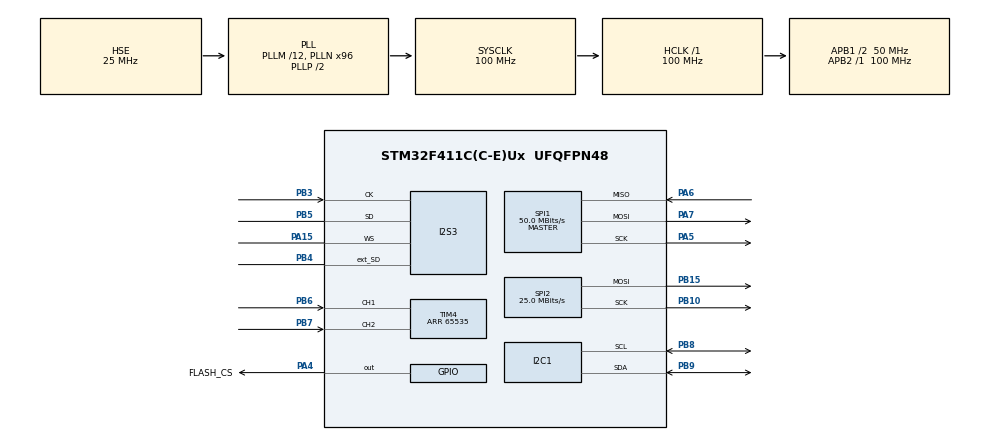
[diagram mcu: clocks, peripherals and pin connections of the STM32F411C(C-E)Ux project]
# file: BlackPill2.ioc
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Mcu.Family=STM32F4
Dma.SPI3_RX.3.Direction=DMA_PERIPH_TO_MEMORY
PA6.Mode=Full_Duplex_Master
RCC.CortexFreq_Value=100000000
SPI1.VirtualType=VM_MASTER
SPI2.VirtualType=VM_MASTER
PB10.Mode=TX_Only_Simplex_Unidirect_Master
TIM4.EncoderMode=TIM_ENCODERMODE_TI12
VP_RTC_VS_RTC_Activate.Mode=RTC_Enabled
Dma.I2S3_EXT_TX.2.PeriphInc=DMA_PINC_DISABLE
Dma.MEMTOMEM.1.FIFOMode=DMA_FIFOMODE_ENABLE
Dma.MEMTOMEM.1.PeriphInc=DMA_PINC_ENABLE
PB15.Signal=SPI2_MOSI
Dma.MEMTOMEM.1.Priority=DMA_PRIORITY_HIGH
RCC.SYSCLKSource=RCC_SYSCLKSOURCE_PLLCLK
ProjectManager.StackSize=0x800
PH0\ -\ OSC_IN.Signal=RCC_OSC_IN
Dma.SPI3_RX.3.MemDataAlignment=DMA_MDATAALIGN_HALFWORD
SPI1.Direction=SPI_DIRECTION_2LINES
RCC.HCLKFreq_Value=100000000
Dma.I2S3_EXT_TX.2.FIFOMode=DMA_FIFOMODE_DISABLE
I2S3.Mode=I2S_MODE_SLAVE_RX
RCC.APB2TimFreq_Value=100000000
PB6.Signal=S_TIM4_CH1
SPI1.CalculateBaudRate=50.0 MBits/s
NVIC.DMA2_Stream0_IRQn=true\:0\:0\:false\:false\:true\:false\:true\:true
RCC.AHBFreq_Value=100000000
RCC.HSE_VALUE=25000000
Dma.SPI3_RX.3.Mode=DMA_CIRCULAR
PB3.Mode=Full_Duplex_Slave
Dma.SPI3_RX.3.Priority=DMA_PRIORITY_VERY_HIGH
PA15.Mode=Full_Duplex_Slave
PA4.GPIO_Speed=GPIO_SPEED_FREQ_HIGH
Dma.MEMTOMEM.1.MemBurst=DMA_MBURST_SINGLE
I2S3.ErrorAudioFreq=-0.35 %
PB4.Mode=Full_Duplex_Slave
PC14-OSC32_IN.Mode=LSE-External-Oscillator
FREERTOS.INCLUDE_xQueueGetMutexHolder=1
PA14.Mode=Serial_Wire
VP_SYS_VS_tim1.Mode=TIM1
Dma.MEMTOMEM.0.Instance=DMA2_Stream0
PB5.Mode=Full_Duplex_Slave
Dma.I2S3_EXT_TX.2.Mode=DMA_CIRCULAR
SPI2.CalculateBaudRate=25.0 MBits/s
SH.S_TIM4_CH2.0=TIM4_CH2,Encoder_Interface
PB7.Signal=S_TIM4_CH2
TIM4.Period=65535
VP_FREERTOS_VS_CMSIS_V1.Mode=CMSIS_V1
Dma.I2S3_EXT_TX.2.Instance=DMA1_Stream5
Dma.I2S3_EXT_TX.2.Direction=DMA_MEMORY_TO_PERIPH
Dma.MEMTOMEM.1.MemInc=DMA_MINC_ENABLE
PB9.Signal=I2C1_SDA
Mcu.Package=UFQFPN48
PA6.Signal=SPI1_MISO
Dma.MEMTOMEM.1.Instance=DMA2_Stream1
NVIC.TimeBase=TIM1_UP_TIM10_IRQn
SPI2.Mode=SPI_MODE_MASTER
Dma.MEMTOMEM.1.PeriphBurst=DMA_PBURST_SINGLE
Dma.MEMTOMEM.0.PeriphInc=DMA_PINC_ENABLE
NVIC.TimeBaseIP=TIM1
PA15.Signal=I2S3_WS
Dma.MEMTOMEM.0.FIFOThreshold=DMA_FIFO_THRESHOLD_FULL
Dma.MEMTOMEM.1.FIFOThreshold=DMA_FIFO_THRESHOLD_FULL
SH.S_TIM4_CH1.0=TIM4_CH1,Encoder_Interface
Dma.Request2=I2S3_EXT_TX
Dma.Request1=MEMTOMEM
RCC.APB1TimFreq_Value=100000000
Dma.Request3=SPI3_RX
Dma.I2S3_EXT_TX.2.PeriphDataAlignment=DMA_PDATAALIGN_HALFWORD
NVIC.DMA1_Stream0_IRQn=true\:5\:0\:false\:false\:true\:true\:false\:true
SPI2.Direction=SPI_DIRECTION_2LINES
Dma.Request0=MEMTOMEM
PA4.GPIO_Label=FLASH_CS
PB4.Signal=I2S3_ext_SD
PA5.Mode=Full_Duplex_Master
RCC.PLLSourceVirtual=RCC_PLLSOURCE_HSE
PC15-OSC32_OUT.Mode=LSE-External-Oscillator
I2S3.FullDuplexMode=I2S_FULLDUPLEXMODE_ENABLE
Dma.MEMTOMEM.0.MemDataAlignment=DMA_MDATAALIGN_HALFWORD
FREERTOS.Tasks01=defaultTask,0,1280,StartDefaultTask,Default,NULL,Dynamic,NULL,NULL;myTask02,0,1280,StartTask02,Default,NULL,Dynamic,NULL,NULL
Dma.I2S3_EXT_TX.2.MemDataAlignment=DMA_MDATAALIGN_HALFWORD
PA7.Mode=Full_Duplex_Master
Dma.MEMTOMEM.0.Priority=DMA_PRIORITY_HIGH
PH1\ -\ OSC_OUT.Mode=HSE-External-Oscillator
ARM.CMSIS.5.6.0.CMSISJjDSP=Library
RCC.APB1CLKDivider=RCC_HCLK_DIV2
PC14-OSC32_IN.Signal=RCC_OSC32_IN
I2S3.DataFormat=I2S_DATAFORMAT_16B
PA13.Signal=SYS_JTMS-SWDIO
PH0\ -\ OSC_IN.Mode=HSE-External-Oscillator
Dma.SPI3_RX.3.MemInc=DMA_MINC_ENABLE
ProjectManager.TargetToolchain=STM32CubeIDE
NVIC.DMA1_Stream5_IRQn=true\:5\:0\:false\:false\:true\:true\:false\:true
VP_ARM.CMSIS_VS_CMSISJjDSP_1.7.0.Mode=CMSISJjDSP
PB9.Mode=I2C
I2S3.VirtualMode=I2S_MODE_SLAVE
Dma.SPI3_RX.3.PeriphInc=DMA_PINC_DISABLE
Dma.MEMTOMEM.0.FIFOMode=DMA_FIFOMODE_ENABLE
PC15-OSC32_OUT.Signal=RCC_OSC32_OUT
PB10.Signal=SPI2_SCK
Dma.MEMTOMEM.0.MemBurst=DMA_MBURST_SINGLE
ARM.CMSIS.5.6.0.CMSISJjCORE=true
PA5.Signal=SPI1_SCK
Dma.MEMTOMEM.1.Mode=DMA_NORMAL
I2S3.AudioFreq=I2S_AUDIOFREQ_96K
PH1\ -\ OSC_OUT.Signal=RCC_OSC_OUT
VP_ARM.CMSIS_VS_CMSISJjCORE_5.3.0.Mode=CMSISJjCORE
board=custom
RCC.VCOOutputFreq_Value=200000000
PB15.Mode=TX_Only_Simplex_Unidirect_Master
Dma.MEMTOMEM.1.MemDataAlignment=DMA_MDATAALIGN_HALFWORD
RCC.APB2Freq_Value=100000000
Dma.MEMTOMEM.1.PeriphDataAlignment=DMA_PDATAALIGN_HALFWORD
SPI1.Mode=SPI_MODE_MASTER
Dma.SPI3_RX.3.FIFOMode=DMA_FIFOMODE_DISABLE
Dma.MEMTOMEM.1.Direction=DMA_MEMORY_TO_MEMORY
PA13.Mode=Serial_Wire
Mcu.Name=STM32F411C(C-E)Ux
FREERTOS.INCLUDE_xSemaphoreGetMutexHolder=1
Dma.MEMTOMEM.0.PeriphDataAlignment=DMA_PDATAALIGN_HALFWORD
RCC.48MHZClocksFreq_Value=40000000
PB3.Signal=I2S3_CK
PA4.Signal=GPIO_Output
RCC.SYSCLKFreq_VALUE=100000000
PB5.Signal=I2S3_SD
FREERTOS.configUSE_COUNTING_SEMAPHORES=1
Dma.MEMTOMEM.0.Mode=DMA_NORMAL
Dma.MEMTOMEM.0.PeriphBurst=DMA_PBURST_SINGLE
Dma.MEMTOMEM.0.MemInc=DMA_MINC_ENABLE
Dma.I2S3_EXT_TX.2.Priority=DMA_PRIORITY_VERY_HIGH
PA14.Signal=SYS_JTCK-SWCLK
ProjectManager.HeapSize=0x200
Dma.SPI3_RX.3.PeriphDataAlignment=DMA_PDATAALIGN_HALFWORD
FREERTOS.configUSE_RECURSIVE_MUTEXES=1
NVIC.TIM1_UP_TIM10_IRQn=true\:0\:0\:false\:false\:true\:false\:false\:true
RCC.HSI_VALUE=16000000
RCC.PLLQ=5
NVIC.PriorityGroup=NVIC_PRIORITYGROUP_4
I2S3.RealAudioFreq=95.663 KHz
RCC.PLLM=12
PB8.Mode=I2C
RCC.PLLN=96
PB8.Signal=I2C1_SCL
Dma.MEMTOMEM.0.Direction=DMA_MEMORY_TO_MEMORY
Dma.SPI3_RX.3.Instance=DMA1_Stream0
I2S3.Instance=SPI$Index
RCC.APB1Freq_Value=50000000
Dma.I2S3_EXT_TX.2.MemInc=DMA_MINC_ENABLE
PA7.Signal=SPI1_MOSI

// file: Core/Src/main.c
/* USER CODE BEGIN Header */
/**
 ******************************************************************************
 * @file           : main.c
 * @brief          : Main program body
 ******************************************************************************
 * @attention
 *
 * <h2><center>&copy; Copyright (c) 2020 STMicroelectronics.
 * All rights reserved.</center></h2>
 *
 * This software component is licensed by ST under BSD 3-Clause license,
 * the "License"; You may not use this file except in compliance with the
 * License. You may obtain a copy of the License at:
 *                        opensource.org/licenses/BSD-3-Clause
 *
 ******************************************************************************
 */
/* USER CODE END Header */

#include "main.h"
#include "cmsis_os.h"

I2C_HandleTypeDef hi2c1;

I2S_HandleTypeDef hi2s3;
DMA_HandleTypeDef hdma_i2s3_ext_rx;
DMA_HandleTypeDef hdma_spi3_tx;

RTC_HandleTypeDef hrtc;

SPI_HandleTypeDef hspi1;
SPI_HandleTypeDef hspi2;

TIM_HandleTypeDef htim4;

DMA_HandleTypeDef hdma_memtomem_dma2_stream0;
DMA_HandleTypeDef hdma_memtomem_dma2_stream1;
osThreadId defaultTaskHandle;
osThreadId myTask02Handle;

void SystemClock_Config(void);
static void MX_GPIO_Init(void);
static void MX_DMA_Init(void);
static void MX_RTC_Init(void);
static void MX_SPI1_Init(void);
static void MX_TIM4_Init(void);
static void MX_I2C1_Init(void);
static void MX_I2S3_Init(void);
static void MX_SPI2_Init(void);
void StartDefaultTask(void const * argument);
void StartTask02(void const * argument);

/* USER CODE BEGIN PFP */
void DMA2_Stream0_TransferComplete(DMA_HandleTypeDef *DmaHandle);
void init(void);
void render(void);
void update(void);
/* USER CODE END PFP */

int main(void)
{

  /* MCU Configuration--------------------------------------------------------*/

  /* Reset of all peripherals, Initializes the Flash interface and the Systick. */
  HAL_Init();

  /* Configure the system clock */
  SystemClock_Config();

  /* Initialize all configured peripherals */
  MX_GPIO_Init();
  MX_DMA_Init();
  MX_RTC_Init();
  MX_SPI1_Init();
  MX_TIM4_Init();
  MX_I2C1_Init();
  MX_I2S3_Init();
  MX_SPI2_Init();
  /* USER CODE BEGIN 2 */

	HAL_DMA_RegisterCallback(&hdma_memtomem_dma2_stream0,
			HAL_DMA_XFER_CPLT_CB_ID, DMA2_Stream0_TransferComplete);

  /* USER CODE END 2 */

  /* Create the thread(s) */
  /* definition and creation of defaultTask */
  osThreadDef(defaultTask, StartDefaultTask, osPriorityNormal, 0, 1280);
  defaultTaskHandle = osThreadCreate(osThread(defaultTask), NULL);

  /* definition and creation of myTask02 */
  osThreadDef(myTask02, StartTask02, osPriorityNormal, 0, 1280);
  myTask02Handle = osThreadCreate(osThread(myTask02), NULL);

  /* Start scheduler */
  osKernelStart();

  /* We should never get here as control is now taken by the scheduler */
  /* Infinite loop */
	while (1) {

	}
}

void SystemClock_Config(void)
{
  RCC_OscInitTypeDef RCC_OscInitStruct = {0};
  RCC_ClkInitTypeDef RCC_ClkInitStruct = {0};
  RCC_PeriphCLKInitTypeDef PeriphClkInitStruct = {0};

  /** Configure the main internal regulator output voltage
  */
  __HAL_RCC_PWR_CLK_ENABLE();
  __HAL_PWR_VOLTAGESCALING_CONFIG(PWR_REGULATOR_VOLTAGE_SCALE1);
  /** Initializes the CPU, AHB and APB busses clocks
  */
  RCC_OscInitStruct.OscillatorType = RCC_OSCILLATORTYPE_LSI|RCC_OSCILLATORTYPE_HSE;
  RCC_OscInitStruct.HSEState = RCC_HSE_ON;
  RCC_OscInitStruct.LSIState = RCC_LSI_ON;
  RCC_OscInitStruct.PLL.PLLState = RCC_PLL_ON;
  RCC_OscInitStruct.PLL.PLLSource = RCC_PLLSOURCE_HSE;
  RCC_OscInitStruct.PLL.PLLM = 12;
  RCC_OscInitStruct.PLL.PLLN = 96;
  RCC_OscInitStruct.PLL.PLLP = RCC_PLLP_DIV2;
  RCC_OscInitStruct.PLL.PLLQ = 5;
  if (HAL_RCC_OscConfig(&RCC_OscInitStruct) != HAL_OK)
  {
    Error_Handler();
  }
  /** Initializes the CPU, AHB and APB busses clocks
  */
  RCC_ClkInitStruct.ClockType = RCC_CLOCKTYPE_HCLK|RCC_CLOCKTYPE_SYSCLK
                              |RCC_CLOCKTYPE_PCLK1|RCC_CLOCKTYPE_PCLK2;
  RCC_ClkInitStruct.SYSCLKSource = RCC_SYSCLKSOURCE_PLLCLK;
  RCC_ClkInitStruct.AHBCLKDivider = RCC_SYSCLK_DIV1;
  RCC_ClkInitStruct.APB1CLKDivider = RCC_HCLK_DIV2;
  RCC_ClkInitStruct.APB2CLKDivider = RCC_HCLK_DIV1;

  if (HAL_RCC_ClockConfig(&RCC_ClkInitStruct, FLASH_LATENCY_3) != HAL_OK)
  {
    Error_Handler();
  }
  PeriphClkInitStruct.PeriphClockSelection = RCC_PERIPHCLK_I2S|RCC_PERIPHCLK_RTC;
  PeriphClkInitStruct.PLLI2S.PLLI2SN = 192;
  PeriphClkInitStruct.PLLI2S.PLLI2SM = 16;
  PeriphClkInitStruct.PLLI2S.PLLI2SR = 2;
  PeriphClkInitStruct.RTCClockSelection = RCC_RTCCLKSOURCE_LSI;
  if (HAL_RCCEx_PeriphCLKConfig(&PeriphClkInitStruct) != HAL_OK)
  {
    Error_Handler();
  }
}

static void MX_I2C1_Init(void)
{

  hi2c1.Instance = I2C1;
  hi2c1.Init.ClockSpeed = 100000;
  hi2c1.Init.DutyCycle = I2C_DUTYCYCLE_2;
  hi2c1.Init.OwnAddress1 = 0;
  hi2c1.Init.AddressingMode = I2C_ADDRESSINGMODE_7BIT;
  hi2c1.Init.DualAddressMode = I2C_DUALADDRESS_DISABLE;
  hi2c1.Init.OwnAddress2 = 0;
  hi2c1.Init.GeneralCallMode = I2C_GENERALCALL_DISABLE;
  hi2c1.Init.NoStretchMode = I2C_NOSTRETCH_DISABLE;
  if (HAL_I2C_Init(&hi2c1) != HAL_OK)
  {
    Error_Handler();
  }

}

static void MX_I2S3_Init(void)
{

  hi2s3.Instance = SPI3;
  hi2s3.Init.Mode = I2S_MODE_SLAVE_TX;
  hi2s3.Init.Standard = I2S_STANDARD_PHILIPS;
  hi2s3.Init.DataFormat = I2S_DATAFORMAT_16B;
  hi2s3.Init.MCLKOutput = I2S_MCLKOUTPUT_DISABLE;
  hi2s3.Init.AudioFreq = I2S_AUDIOFREQ_96K;
  hi2s3.Init.CPOL = I2S_CPOL_LOW;
  hi2s3.Init.ClockSource = I2S_CLOCK_PLL;
  hi2s3.Init.FullDuplexMode = I2S_FULLDUPLEXMODE_ENABLE;
  if (HAL_I2S_Init(&hi2s3) != HAL_OK)
  {
    Error_Handler();
  }

}

static void MX_RTC_Init(void)
{

  /** Initialize RTC Only
  */
  hrtc.Instance = RTC;
  hrtc.Init.HourFormat = RTC_HOURFORMAT_24;
  hrtc.Init.AsynchPrediv = 127;
  hrtc.Init.SynchPrediv = 255;
  hrtc.Init.OutPut = RTC_OUTPUT_DISABLE;
  hrtc.Init.OutPutPolarity = RTC_OUTPUT_POLARITY_HIGH;
  hrtc.Init.OutPutType = RTC_OUTPUT_TYPE_OPENDRAIN;
  if (HAL_RTC_Init(&hrtc) != HAL_OK)
  {
    Error_Handler();
  }

}

static void MX_SPI1_Init(void)
{

  /* SPI1 parameter configuration*/
  hspi1.Instance = SPI1;
  hspi1.Init.Mode = SPI_MODE_MASTER;
  hspi1.Init.Direction = SPI_DIRECTION_2LINES;
  hspi1.Init.DataSize = SPI_DATASIZE_8BIT;
  hspi1.Init.CLKPolarity = SPI_POLARITY_LOW;
  hspi1.Init.CLKPhase = SPI_PHASE_1EDGE;
  hspi1.Init.NSS = SPI_NSS_SOFT;
  hspi1.Init.BaudRatePrescaler = SPI_BAUDRATEPRESCALER_2;
  hspi1.Init.FirstBit = SPI_FIRSTBIT_MSB;
  hspi1.Init.TIMode = SPI_TIMODE_DISABLE;
  hspi1.Init.CRCCalculation = SPI_CRCCALCULATION_DISABLE;
  hspi1.Init.CRCPolynomial = 10;
  if (HAL_SPI_Init(&hspi1) != HAL_OK)
  {
    Error_Handler();
  }

}

static void MX_SPI2_Init(void)
{

  /* SPI2 parameter configuration*/
  hspi2.Instance = SPI2;
  hspi2.Init.Mode = SPI_MODE_MASTER;
  hspi2.Init.Direction = SPI_DIRECTION_2LINES;
  hspi2.Init.DataSize = SPI_DATASIZE_8BIT;
  hspi2.Init.CLKPolarity = SPI_POLARITY_LOW;
  hspi2.Init.CLKPhase = SPI_PHASE_1EDGE;
  hspi2.Init.NSS = SPI_NSS_SOFT;
  hspi2.Init.BaudRatePrescaler = SPI_BAUDRATEPRESCALER_2;
  hspi2.Init.FirstBit = SPI_FIRSTBIT_MSB;
  hspi2.Init.TIMode = SPI_TIMODE_DISABLE;
  hspi2.Init.CRCCalculation = SPI_CRCCALCULATION_DISABLE;
  hspi2.Init.CRCPolynomial = 10;
  if (HAL_SPI_Init(&hspi2) != HAL_OK)
  {
    Error_Handler();
  }

}

static void MX_TIM4_Init(void)
{

  TIM_Encoder_InitTypeDef sConfig = {0};
  TIM_MasterConfigTypeDef sMasterConfig = {0};

  htim4.Instance = TIM4;
  htim4.Init.Prescaler = 0;
  htim4.Init.CounterMode = TIM_COUNTERMODE_UP;
  htim4.Init.Period = 65535;
  htim4.Init.ClockDivision = TIM_CLOCKDIVISION_DIV1;
  htim4.Init.AutoReloadPreload = TIM_AUTORELOAD_PRELOAD_DISABLE;
  sConfig.EncoderMode = TIM_ENCODERMODE_TI12;
  sConfig.IC1Polarity = TIM_ICPOLARITY_RISING;
  sConfig.IC1Selection = TIM_ICSELECTION_DIRECTTI;
  sConfig.IC1Prescaler = TIM_ICPSC_DIV1;
  sConfig.IC1Filter = 0;
  sConfig.IC2Polarity = TIM_ICPOLARITY_RISING;
  sConfig.IC2Selection = TIM_ICSELECTION_DIRECTTI;
  sConfig.IC2Prescaler = TIM_ICPSC_DIV1;
  sConfig.IC2Filter = 0;
  if (HAL_TIM_Encoder_Init(&htim4, &sConfig) != HAL_OK)
  {
    Error_Handler();
  }
  sMasterConfig.MasterOutputTrigger = TIM_TRGO_RESET;
  sMasterConfig.MasterSlaveMode = TIM_MASTERSLAVEMODE_DISABLE;
  if (HAL_TIMEx_MasterConfigSynchronization(&htim4, &sMasterConfig) != HAL_OK)
  {
    Error_Handler();
  }

}

static void MX_DMA_Init(void)
{

  /* DMA controller clock enable */
  __HAL_RCC_DMA2_CLK_ENABLE();
  __HAL_RCC_DMA1_CLK_ENABLE();

  /* Configure DMA request hdma_memtomem_dma2_stream0 on DMA2_Stream0 */
  hdma_memtomem_dma2_stream0.Instance = DMA2_Stream0;
  hdma_memtomem_dma2_stream0.Init.Channel = DMA_CHANNEL_0;
  hdma_memtomem_dma2_stream0.Init.Direction = DMA_MEMORY_TO_MEMORY;
  hdma_memtomem_dma2_stream0.Init.PeriphInc = DMA_PINC_ENABLE;
  hdma_memtomem_dma2_stream0.Init.MemInc = DMA_MINC_ENABLE;
  hdma_memtomem_dma2_stream0.Init.PeriphDataAlignment = DMA_PDATAALIGN_HALFWORD;
  hdma_memtomem_dma2_stream0.Init.MemDataAlignment = DMA_MDATAALIGN_HALFWORD;
  hdma_memtomem_dma2_stream0.Init.Mode = DMA_NORMAL;
  hdma_memtomem_dma2_stream0.Init.Priority = DMA_PRIORITY_HIGH;
  hdma_memtomem_dma2_stream0.Init.FIFOMode = DMA_FIFOMODE_ENABLE;
  hdma_memtomem_dma2_stream0.Init.FIFOThreshold = DMA_FIFO_THRESHOLD_FULL;
  hdma_memtomem_dma2_stream0.Init.MemBurst = DMA_MBURST_SINGLE;
  hdma_memtomem_dma2_stream0.Init.PeriphBurst = DMA_PBURST_SINGLE;
  if (HAL_DMA_Init(&hdma_memtomem_dma2_stream0) != HAL_OK)
  {
    Error_Handler( );
  }

  /* Configure DMA request hdma_memtomem_dma2_stream1 on DMA2_Stream1 */
  hdma_memtomem_dma2_stream1.Instance = DMA2_Stream1;
  hdma_memtomem_dma2_stream1.Init.Channel = DMA_CHANNEL_0;
  hdma_memtomem_dma2_stream1.Init.Direction = DMA_MEMORY_TO_MEMORY;
  hdma_memtomem_dma2_stream1.Init.PeriphInc = DMA_PINC_ENABLE;
  hdma_memtomem_dma2_stream1.Init.MemInc = DMA_MINC_ENABLE;
  hdma_memtomem_dma2_stream1.Init.PeriphDataAlignment = DMA_PDATAALIGN_HALFWORD;
  hdma_memtomem_dma2_stream1.Init.MemDataAlignment = DMA_MDATAALIGN_HALFWORD;
  hdma_memtomem_dma2_stream1.Init.Mode = DMA_NORMAL;
  hdma_memtomem_dma2_stream1.Init.Priority = DMA_PRIORITY_HIGH;
  hdma_memtomem_dma2_stream1.Init.FIFOMode = DMA_FIFOMODE_ENABLE;
  hdma_memtomem_dma2_stream1.Init.FIFOThreshold = DMA_FIFO_THRESHOLD_FULL;
  hdma_memtomem_dma2_stream1.Init.MemBurst = DMA_MBURST_SINGLE;
  hdma_memtomem_dma2_stream1.Init.PeriphBurst = DMA_PBURST_SINGLE;
  if (HAL_DMA_Init(&hdma_memtomem_dma2_stream1) != HAL_OK)
  {
    Error_Handler( );
  }

  /* DMA interrupt init */
  /* DMA1_Stream0_IRQn interrupt configuration */
  HAL_NVIC_SetPriority(DMA1_Stream0_IRQn, 5, 0);
  HAL_NVIC_EnableIRQ(DMA1_Stream0_IRQn);
  /* DMA1_Stream5_IRQn interrupt configuration */
  HAL_NVIC_SetPriority(DMA1_Stream5_IRQn, 5, 0);
  HAL_NVIC_EnableIRQ(DMA1_Stream5_IRQn);
  /* DMA2_Stream0_IRQn interrupt configuration */
  HAL_NVIC_SetPriority(DMA2_Stream0_IRQn, 0, 0);
  HAL_NVIC_EnableIRQ(DMA2_Stream0_IRQn);

}

static void MX_GPIO_Init(void)
{
  GPIO_InitTypeDef GPIO_InitStruct = {0};

  /* GPIO Ports Clock Enable */
  __HAL_RCC_GPIOC_CLK_ENABLE();
  __HAL_RCC_GPIOH_CLK_ENABLE();
  __HAL_RCC_GPIOA_CLK_ENABLE();
  __HAL_RCC_GPIOB_CLK_ENABLE();

  /*Configure GPIO pin Output Level */
  HAL_GPIO_WritePin(FLASH_CS_GPIO_Port, FLASH_CS_Pin, GPIO_PIN_RESET);

  /*Configure GPIO pin : FLASH_CS_Pin */
  GPIO_InitStruct.Pin = FLASH_CS_Pin;
  GPIO_InitStruct.Mode = GPIO_MODE_OUTPUT_PP;
  GPIO_InitStruct.Pull = GPIO_NOPULL;
  GPIO_InitStruct.Speed = GPIO_SPEED_FREQ_HIGH;
  HAL_GPIO_Init(FLASH_CS_GPIO_Port, &GPIO_InitStruct);

}

void StartDefaultTask(void const * argument)
{
  /* USER CODE BEGIN 5 */
	init();
	/* Infinite loop */
	for (;;) {
		render();
		osDelay(1);
	}
  /* USER CODE END 5 */
}

void StartTask02(void const * argument)
{
  /* USER CODE BEGIN StartTask02 */
  /* Infinite loop */
  for(;;)
  {
	  update();
    osDelay(1);
  }
  /* USER CODE END StartTask02 */
}

 /**
  * @brief  Period elapsed callback in non blocking mode
  * @note   This function is called  when TIM1 interrupt took place, inside
  * HAL_TIM_IRQHandler(). It makes a direct call to HAL_IncTick() to increment
  * a global variable "uwTick" used as application time base.
  * @param  htim : TIM handle
  * @retval None
  */
void HAL_TIM_PeriodElapsedCallback(TIM_HandleTypeDef *htim)
{
  if (htim->Instance == TIM1) {
    HAL_IncTick();
  }
}

void Error_Handler(void)
{
}

/************************ (C) COPYRIGHT STMicroelectronics *****END OF FILE****/
